AUTOSAR XML (schema 4-0-3)
standard types defined: Boolean, UInt16, UInt32
package /AUTOSAR_Platform/DataConstrs
  range DC_Boolean: raw 0..1
  range DC_UInt16: raw 0..65535
package /PATAC/Facility/DataTypes/Implementation
  compu method COMPU_Boolean: 0=FALSE, 1=TRUE
  unit NoUnit: factor-si-to-unit=1, offset-si-to-unit=0
package /PATAC/MSM/ComponentTypes
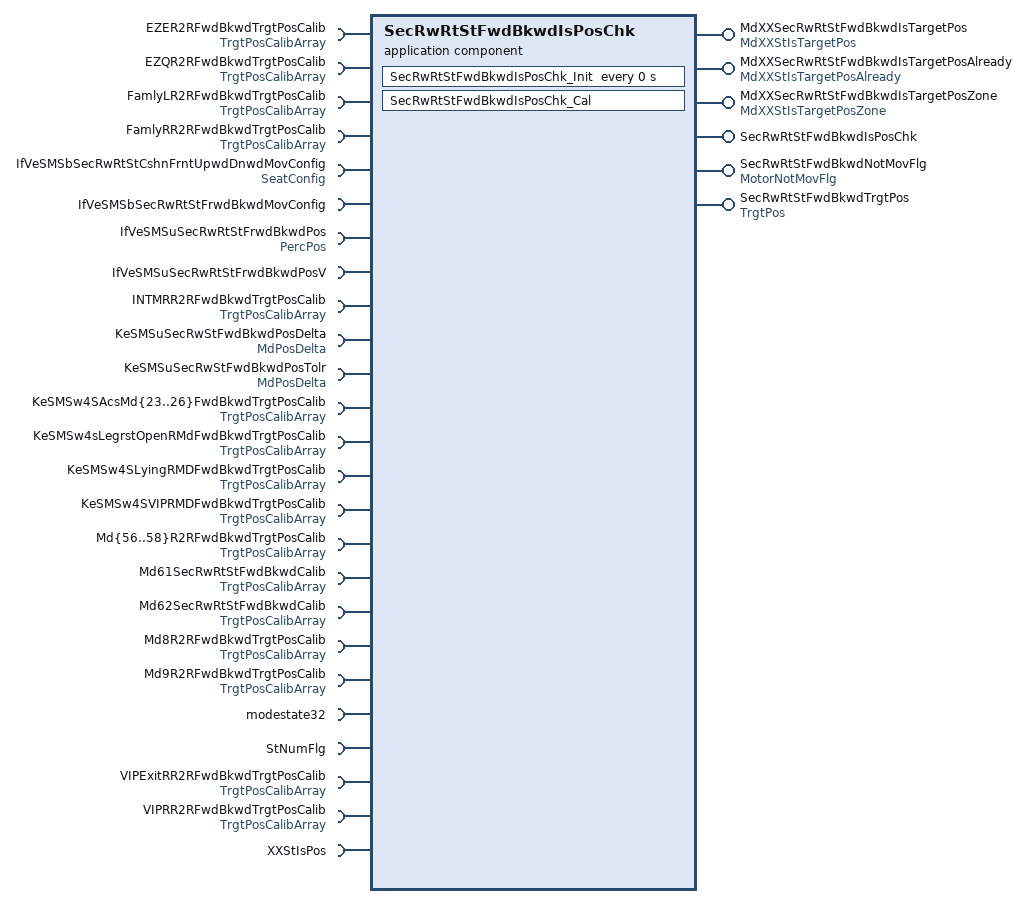
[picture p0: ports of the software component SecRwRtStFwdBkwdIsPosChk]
  application sw component type SecRwRtStFwdBkwdIsPosChk
    6 x provide port:
      MdXXSecRwRtStFwdBkwdIsTargetPos: nonqueued-sender-com-spec{data-element=MdXXStIsTargetPos/Val, init-value=0}, provided-interface=MdXXStIsTargetPos
      MdXXSecRwRtStFwdBkwdIsTargetPosAlready: nonqueued-sender-com-spec{data-element=MdXXStIsTargetPosAlready/Val, init-value=0}, provided-interface=MdXXStIsTargetPosAlready
      MdXXSecRwRtStFwdBkwdIsTargetPosZone: nonqueued-sender-com-spec{data-element=MdXXStIsTargetPosZone/Val, init-value=0}, provided-interface=MdXXStIsTargetPosZone
      SecRwRtStFwdBkwdIsPosChk: server-com-spec{operation=Cal, queue-length=1}, provided-interface=SecRwRtStFwdBkwdIsPosChk
      SecRwRtStFwdBkwdNotMovFlg: nonqueued-sender-com-spec{data-element=MotorNotMovFlg/Val, init-value=0}, provided-interface=MotorNotMovFlg
      SecRwRtStFwdBkwdTrgtPos: nonqueued-sender-com-spec{data-element=TrgtPos/Val, init-value=4095}, provided-interface=TrgtPos
    30 x require port:
      EZER2RFwdBkwdTrgtPosCalib: nonqueued-receiver-com-spec{data-element=TrgtPosArray, filter=data-filter-type=ALWAYS, init-value=[4095, 4095, 4095]}, required-interface=TrgtPosCalibArray
      EZQR2RFwdBkwdTrgtPosCalib: nonqueued-receiver-com-spec{data-element=TrgtPosArray, filter=data-filter-type=ALWAYS, init-value=[4095, 4095, 4095]}, required-interface=TrgtPosCalibArray
      FamlyLR2RFwdBkwdTrgtPosCalib: nonqueued-receiver-com-spec{data-element=TrgtPosArray, filter=data-filter-type=ALWAYS, init-value=[4095, 4095, 4095]}, required-interface=TrgtPosCalibArray
      FamlyRR2RFwdBkwdTrgtPosCalib: nonqueued-receiver-com-spec{data-element=TrgtPosArray, filter=data-filter-type=ALWAYS, init-value=[4095, 4095, 4095]}, required-interface=TrgtPosCalibArray
      IfVeSMSbSecRwRtStCshnFrntUpwdDnwdMovConfig: nonqueued-receiver-com-spec{data-element=SeatConfig/Val, filter=data-filter-type=ALWAYS, init-value=0}, required-interface=SeatConfig
      IfVeSMSbSecRwRtStFrwdBkwdMovConfig: nonqueued-receiver-com-spec{data-element=IfVeSMSbSecRwRtStFrwdBkwdMovConfig/Val, filter=data-filter-type=ALWAYS, init-value=0}, required-interface=IfVeSMSbSecRwRtStFrwdBkwdMovConfig
      IfVeSMSuSecRwRtStFrwdBkwdPos: nonqueued-receiver-com-spec{data-element=PercPos/Val, filter=data-filter-type=ALWAYS, init-value=0}, required-interface=PercPos
      IfVeSMSuSecRwRtStFrwdBkwdPosV: nonqueued-receiver-com-spec{data-element=IfVeSMSuSecRwRtStFrwdBkwdPosV/Val, filter=data-filter-type=ALWAYS, init-value=0}, required-interface=IfVeSMSuSecRwRtStFrwdBkwdPosV
      INTMRR2RFwdBkwdTrgtPosCalib: nonqueued-receiver-com-spec{data-element=TrgtPosArray, filter=data-filter-type=ALWAYS, init-value=[4095, 4095, 4095]}, required-interface=TrgtPosCalibArray
      KeSMSuSecRwStFwdBkwdPosDelta: parameter-require-com-spec{init-value=KeSMSuSecRwStFwdBkwdPosDelta_Val:300, parameter=Val}, required-interface=MdPosDelta
      KeSMSuSecRwStFwdBkwdPosTolr: parameter-require-com-spec{init-value=KeSMSuSecRwStFwdBkwdPosTolr_Val:300, parameter=Val}, required-interface=MdPosDelta
      KeSMSw4SAcsMd{23..26}FwdBkwdTrgtPosCalib: nonqueued-receiver-com-spec{data-element=TrgtPosArray, filter=data-filter-type=ALWAYS, init-value=[4095, 4095, 4095]}, required-interface=TrgtPosCalibArray
      KeSMSw4sLegrstOpenRMdFwdBkwdTrgtPosCalib: nonqueued-receiver-com-spec{data-element=TrgtPosArray, filter=data-filter-type=ALWAYS, init-value=[4095, 4095, 4095]}, required-interface=TrgtPosCalibArray
      KeSMSw4SLyingRMDFwdBkwdTrgtPosCalib: nonqueued-receiver-com-spec{data-element=TrgtPosArray, filter=data-filter-type=ALWAYS, init-value=[4095, 4095, 4095]}, required-interface=TrgtPosCalibArray
      KeSMSw4SVIPRMDFwdBkwdTrgtPosCalib: nonqueued-receiver-com-spec{data-element=TrgtPosArray, filter=data-filter-type=ALWAYS, init-value=[4095, 4095, 4095]}, required-interface=TrgtPosCalibArray
      Md{56..58}R2RFwdBkwdTrgtPosCalib: nonqueued-receiver-com-spec{data-element=TrgtPosArray, filter=data-filter-type=ALWAYS, init-value=[4095, 4095, 4095]}, required-interface=TrgtPosCalibArray
      Md61SecRwRtStFwdBkwdCalib: nonqueued-receiver-com-spec{data-element=TrgtPosArray, filter=data-filter-type=ALWAYS, init-value=[4095, 4095, 4095]}, required-interface=TrgtPosCalibArray
      Md62SecRwRtStFwdBkwdCalib: nonqueued-receiver-com-spec{data-element=TrgtPosArray, filter=data-filter-type=ALWAYS, init-value=[4095, 4095, 4095]}, required-interface=TrgtPosCalibArray
      Md8R2RFwdBkwdTrgtPosCalib: nonqueued-receiver-com-spec{data-element=TrgtPosArray, filter=data-filter-type=ALWAYS, init-value=[4095, 4095, 4095]}, required-interface=TrgtPosCalibArray
      Md9R2RFwdBkwdTrgtPosCalib: nonqueued-receiver-com-spec{data-element=TrgtPosArray, filter=data-filter-type=ALWAYS, init-value=[4095, 4095, 4095]}, required-interface=TrgtPosCalibArray
      modestate32: nonqueued-receiver-com-spec{data-element=modestate32/Val, filter=data-filter-type=ALWAYS, init-value=0}, required-interface=modestate32
      StNumFlg: required-interface=StNumFlg
        required-com-specs:
          data-element=Is4s, filter=data-filter-type=ALWAYS, init-value=0
          data-element=Is6s, filter=data-filter-type=ALWAYS, init-value=0
          data-element=Is6s7s, filter=data-filter-type=ALWAYS, init-value=0
          data-element=Is7s, filter=data-filter-type=ALWAYS, init-value=0
      VIPExitRR2RFwdBkwdTrgtPosCalib: nonqueued-receiver-com-spec{data-element=TrgtPosArray, filter=data-filter-type=ALWAYS, init-value=[4095, 4095, 4095]}, required-interface=TrgtPosCalibArray
      VIPRR2RFwdBkwdTrgtPosCalib: nonqueued-receiver-com-spec{data-element=TrgtPosArray, filter=data-filter-type=ALWAYS, init-value=[4095, 4095, 4095]}, required-interface=TrgtPosCalibArray
      XXStIsPos: client-com-spec=Get, required-interface=XXStIsPos
    behavior SecRwRtStFwdBkwdIsPosChk_InternalBehavior
      operation invoked event OIT_SecRwRtStFwdBkwdIsPosChk_Cal_SecRwRtStFwdBkwdIsPosChk_Cal: start-on-event=SecRwRtStFwdBkwdIsPosChk_Cal, operation=SecRwRtStFwdBkwdIsPosChk.Cal
      timing event SecRwRtStFwdBkwdIsPosChk_InitEvent: start-on-event=SecRwRtStFwdBkwdIsPosChk_Init, period=0
      runnable SecRwRtStFwdBkwdIsPosChk_Cal
        data-receive-point-by-arguments:
          30 x access:
            IN_EZER2RFwdBkwdTrgtPosCalib_TrgtPosArray: accessed-variable=EZER2RFwdBkwdTrgtPosCalib.TrgtPosArray
            IN_EZQR2RFwdBkwdTrgtPosCalib_TrgtPosArray: accessed-variable=EZQR2RFwdBkwdTrgtPosCalib.TrgtPosArray
            IN_FamlyLR2RFwdBkwdTrgtPosCalib_TrgtPosArray: accessed-variable=FamlyLR2RFwdBkwdTrgtPosCalib.TrgtPosArray
            IN_FamlyRR2RFwdBkwdTrgtPosCalib_TrgtPosArray: accessed-variable=FamlyRR2RFwdBkwdTrgtPosCalib.TrgtPosArray
            IN_IfVeSMSbSecRwRtStFrwdBkwdMovConfig_Val: accessed-variable=IfVeSMSbSecRwRtStFrwdBkwdMovConfig.Val
            IN_IfVeSMSuSecRwRtStFrwdBkwdPos_Val: accessed-variable=IfVeSMSuSecRwRtStFrwdBkwdPos.Val
            IN_IfVeSMSuSecRwRtStFrwdBkwdPosV_Val: accessed-variable=IfVeSMSuSecRwRtStFrwdBkwdPosV.Val
            IN_INTMRR2RFwdBkwdTrgtPosCalib_TrgtPosArray: accessed-variable=INTMRR2RFwdBkwdTrgtPosCalib.TrgtPosArray
            IN_KeSMSw4SAcsMd{23..26}FwdBkwdTrgtPosCalib_TrgtPosArray: accessed-variable=KeSMSw4SAcsMd{23..26}FwdBkwdTrgtPosCalib.TrgtPosArray
            IN_modestate32_Val: accessed-variable=modestate32.Val
            IN_VIPRR2RFwdBkwdTrgtPosCalib_TrgtPosArray: accessed-variable=VIPRR2RFwdBkwdTrgtPosCalib.TrgtPosArray
            REC_IfVeSMSbSecRwRtStCshnFrntUpwdDnwdMovConfig_Val: accessed-variable=IfVeSMSbSecRwRtStCshnFrntUpwdDnwdMovConfig.Val
            REC_KeSMSw4sLegrstOpenRMdFwdBkwdTrgtPosCalib_TrgtPosArray: accessed-variable=KeSMSw4sLegrstOpenRMdFwdBkwdTrgtPosCalib.TrgtPosArray
            REC_KeSMSw4SLyingRMDFwdBkwdTrgtPosCalib_TrgtPosArray: accessed-variable=KeSMSw4SLyingRMDFwdBkwdTrgtPosCalib.TrgtPosArray
            REC_KeSMSw4SVIPRMDFwdBkwdTrgtPosCalib_TrgtPosArray: accessed-variable=KeSMSw4SVIPRMDFwdBkwdTrgtPosCalib.TrgtPosArray
            REC_Md{56..58}R2RFwdBkwdTrgtPosCalib_TrgtPosArray: accessed-variable=Md{56..58}R2RFwdBkwdTrgtPosCalib.TrgtPosArray
            REC_Md61SecRwRtStFwdBkwdCalib_TrgtPosArray: accessed-variable=Md61SecRwRtStFwdBkwdCalib.TrgtPosArray
            REC_Md62SecRwRtStFwdBkwdCalib_TrgtPosArray: accessed-variable=Md62SecRwRtStFwdBkwdCalib.TrgtPosArray
            REC_Md8R2RFwdBkwdTrgtPosCalib_TrgtPosArray: accessed-variable=Md8R2RFwdBkwdTrgtPosCalib.TrgtPosArray
            REC_Md9R2RFwdBkwdTrgtPosCalib_TrgtPosArray: accessed-variable=Md9R2RFwdBkwdTrgtPosCalib.TrgtPosArray
            REC_StNumFlg_Is4s: accessed-variable=StNumFlg.Is4s
            REC_StNumFlg_Is6s: accessed-variable=StNumFlg.Is6s
            REC_StNumFlg_Is6s7s: accessed-variable=StNumFlg.Is6s7s
            REC_StNumFlg_Is7s: accessed-variable=StNumFlg.Is7s
            REC_VIPExitRR2RFwdBkwdTrgtPosCalib_TrgtPosArray: accessed-variable=VIPExitRR2RFwdBkwdTrgtPosCalib.TrgtPosArray
        data-send-points:
          5 x access:
            OUT_MdXXSecRwRtStFwdBkwdIsTargetPos_Val: accessed-variable=MdXXSecRwRtStFwdBkwdIsTargetPos.Val
            OUT_MdXXSecRwRtStFwdBkwdIsTargetPosAlready_Val: accessed-variable=MdXXSecRwRtStFwdBkwdIsTargetPosAlready.Val
            OUT_MdXXSecRwRtStFwdBkwdIsTargetPosZone_Val: accessed-variable=MdXXSecRwRtStFwdBkwdIsTargetPosZone.Val
            OUT_SecRwRtStFwdBkwdNotMovFlg_Val: accessed-variable=SecRwRtStFwdBkwdNotMovFlg.Val
            OUT_SecRwRtStFwdBkwdTrgtPos_Val: accessed-variable=SecRwRtStFwdBkwdTrgtPos.Val
        parameter access PA_KeSMSuSecRwStFwdBkwdPosDelta_Val: accessed-parameter=KeSMSuSecRwStFwdBkwdPosDelta.Val
        parameter access PA_KeSMSuSecRwStFwdBkwdPosTolr_Val: accessed-parameter=KeSMSuSecRwStFwdBkwdPosTolr.Val
        sync call SC_XXStIsPos_Get: operation=XXStIsPos.Get, timeout=0
      runnable SecRwRtStFwdBkwdIsPosChk_Init
        parameter access PA_KeSMSuSecRwStFwdBkwdPosDelta_Val: accessed-parameter=KeSMSuSecRwStFwdBkwdPosDelta.Val
        parameter access PA_KeSMSuSecRwStFwdBkwdPosTolr_Val: accessed-parameter=KeSMSuSecRwStFwdBkwdPosTolr.Val
  swc implementation SecRwRtStFwdBkwdIsPosChk_Implementation: behavior=SecRwRtStFwdBkwdIsPosChk_InternalBehavior
    code-descriptors:
      code Default: artifact-descriptors=autosar-engineering-object={short-label=Default, category=SWSRC}
package /PATAC/MSM/ModeAdjust/CalPortInterface
  parameter interface MdPosDelta
    parameter data prototype Val: sw-calibration-access=READ-WRITE, type=UInt16
package /PATAC/MSM/ModeAdjust/DataType
  impl type TrgtPosCalibArray: category=ARRAY, sw-calibration-access=READ-ONLY, type-emitter=RTE  # 0:pos 1:max 2:min
    element Element: array-size=3, array-size-semantics=FIXED-SIZE, implementation-data-type=UInt16, invalid-value=0
package /PATAC/MSM/ModeAdjust/Interfaces
  sender receiver interface IfVeSMSuSecRwRtStFrwdBkwdPosV: invalidation-policy{data-element=IfVeSMSuSecRwRtStFrwdBkwdPosV/Val, handle-invalid=DONT-INVALIDATE}
    data Val: type=Implementation/Boolean
package /PATAC/MSM/ModeAdjust/PortInterface
  client server interface SecRwRtStFwdBkwdIsPosChk
    operation Cal
  client server interface XXStIsPos
    operation Get
      8 x arg, all with server-argument-impl-policy=USE-ARGUMENT-TYPE:
        PosV: type=DataTypes/Boolean, direction=IN
        Pos: type=UInt16, direction=IN
        CalibArray: type=TrgtPosCalibArray, direction=IN
        Delta: type=UInt16, direction=IN
        Tolr: type=UInt16, direction=IN
        IsPos: type=DataTypes/Boolean, direction=OUT
        IsPosZone: type=DataTypes/Boolean, direction=OUT
        IsPosAlready: type=DataTypes/Boolean, direction=OUT
  8 x sender receiver interface:
    MdXXStIsTargetPos: invalidation-policy{data-element=MdXXStIsTargetPos/Val, handle-invalid=DONT-INVALIDATE}
      data Val: type=UInt32
    MdXXStIsTargetPosAlready: invalidation-policy{data-element=MdXXStIsTargetPosAlready/Val, handle-invalid=DONT-INVALIDATE}
      data Val: type=UInt32
    MdXXStIsTargetPosZone: invalidation-policy{data-element=MdXXStIsTargetPosZone/Val, handle-invalid=DONT-INVALIDATE}
      data Val: type=UInt32
    modestate32: invalidation-policy{data-element=modestate32/Val, handle-invalid=DONT-INVALIDATE}
      data Val: type=UInt32
    MotorNotMovFlg: invalidation-policy{data-element=MotorNotMovFlg/Val, handle-invalid=DONT-INVALIDATE}
      data Val: type=Implementation/Boolean
    PercPos: invalidation-policy{data-element=PercPos/Val, handle-invalid=DONT-INVALIDATE}
      data Val: type=UInt16
    StNumFlg
      4 x data, all with type=Implementation/Boolean:
        Is4s
        Is6s
        Is6s7s
        Is7s
      invalidation-policys:
        data-element=Is4s, handle-invalid=DONT-INVALIDATE
        data-element=Is6s, handle-invalid=DONT-INVALIDATE
        data-element=Is6s7s, handle-invalid=DONT-INVALIDATE
        data-element=Is7s, handle-invalid=DONT-INVALIDATE
    TrgtPosCalibArray: invalidation-policy{data-element=TrgtPosArray, handle-invalid=DONT-INVALIDATE}
      data TrgtPosArray: type=TrgtPosCalibArray  # 0:Pos 1:Max 2:Min
package /PATAC/MSM/PortInterfaces
  sender receiver interface IfVeSMSbSecRwRtStFrwdBkwdMovConfig: invalidation-policy{data-element=IfVeSMSbSecRwRtStFrwdBkwdMovConfig/Val, handle-invalid=DONT-INVALIDATE}
    data Val: type=Implementation/Boolean
  sender receiver interface SeatConfig: invalidation-policy{data-element=SeatConfig/Val, handle-invalid=DONT-INVALIDATE}
    data Val: type=Implementation/Boolean
  sender receiver interface TrgtPos: invalidation-policy{data-element=TrgtPos/Val, handle-invalid=DONT-INVALIDATE}
    data Val: type=UInt16
